# MK21F12 register map
Vendor: Freescale Semiconductor, Inc.; Series: Kinetis_K; File version: 1.6
CPU: CM4 r0p1, little endian, no MPU, FPU, VTOR, 4 interrupt priority bits
Registers are 32-bit, read-write, reset 0x0 unless marked. A register's access mark holds for its fields unless they carry their own. Offsets are from the block's base; [hi:lo] are bit positions; {n}, {i} and the like mark numbered series; 'fields as' and 'values as' point back to an identical list.

## FTFE_FlashConfig — Flash configuration field
Base 0x00000400; register names take the prefix NV_
0x00 BACKKEY3 8-bit ro reset 0xFF — Backdoor Comparison Key 3.
  [7:0] KEY — Backdoor Comparison Key.
0x01 BACKKEY2 8-bit ro reset 0xFF — Backdoor Comparison Key 2.
  [7:0] KEY — Backdoor Comparison Key.
0x02 BACKKEY1 8-bit ro reset 0xFF — Backdoor Comparison Key 1.
  [7:0] KEY — Backdoor Comparison Key.
0x03 BACKKEY0 8-bit ro reset 0xFF — Backdoor Comparison Key 0.
  [7:0] KEY — Backdoor Comparison Key.
0x04 BACKKEY7 8-bit ro reset 0xFF — Backdoor Comparison Key 7.
  [7:0] KEY — Backdoor Comparison Key.
0x05 BACKKEY6 8-bit ro reset 0xFF — Backdoor Comparison Key 6.
  [7:0] KEY — Backdoor Comparison Key.
0x06 BACKKEY5 8-bit ro reset 0xFF — Backdoor Comparison Key 5.
  [7:0] KEY — Backdoor Comparison Key.
0x07 BACKKEY4 8-bit ro reset 0xFF — Backdoor Comparison Key 4.
  [7:0] KEY — Backdoor Comparison Key.
0x08 FPROT3 8-bit ro reset 0xFF — Non-volatile P-Flash Protection 1 - Low Register
  [7:0] PROT — P-Flash Region Protect
0x09 FPROT2 8-bit ro reset 0xFF — Non-volatile P-Flash Protection 1 - High Register
  [7:0] PROT — P-Flash Region Protect
0x0A FPROT1 8-bit ro reset 0xFF — Non-volatile P-Flash Protection 0 - Low Register
  [7:0] PROT — P-Flash Region Protect
0x0B FPROT0 8-bit ro reset 0xFF — Non-volatile P-Flash Protection 0 - High Register
  [7:0] PROT — P-Flash Region Protect
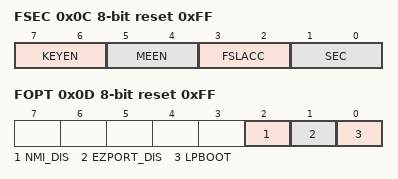
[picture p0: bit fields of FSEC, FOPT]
0x0C FSEC 8-bit ro reset 0xFF — Non-volatile Flash Security Register
  [7:6] KEYEN — Backdoor Key Security Enable
    2=Backdoor key access enabled; 3=Backdoor key access disabled
  [5:4] MEEN
    2=Mass erase is disabled; 3=Mass erase is enabled
  [3:2] FSLACC — Freescale Failure Analysis Access Code
    2=Freescale factory access denied; 3=Freescale factory access granted
  [1:0] SEC — Flash Security
    2=MCU security status is unsecure; 3=MCU security status is secure
0x0D FOPT 8-bit ro reset 0xFF — Non-volatile Flash Option Register
  [2] NMI_DIS
    0=NMI interrupts are always blocked; 1=NMI_b pin/interrupts reset default to enabled
  [1] EZPORT_DIS
    0=EzPort operation is disabled; 1=EzPort operation is enabled
  [0] LPBOOT
    0=Low-power boot; 1=Normal boot
0x0E FEPROT 8-bit ro reset 0xFF — Non-volatile EERAM Protection Register
  [7:0] EPROT
0x0F FDPROT 8-bit ro reset 0xFF — Non-volatile D-Flash Protection Register
  [7:0] DPROT — D-Flash Region Protect

## AXBS — Crossbar switch
Base 0x40004000; register names take the prefix AXBS_
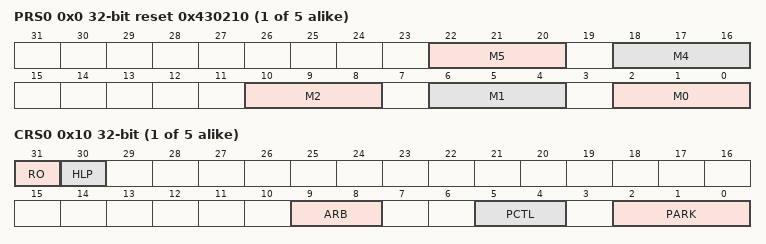
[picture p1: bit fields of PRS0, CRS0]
{0x0+0x100*i} PRS{i} (i=0..4) reset 0x430210 — Priority Registers Slave
  [all] fields
    0=This master has level 1, or highest, priority when accessing the slave port; {v}=This master has level {v+1} priority when accessing the slave port (v=1..6); 7=This master has level 8, or lowest, priority when accessing the slave port
  [22:20] M5 — Master 5 Priority. Sets the arbitration priority for this port on the associated slave port.
  [18:16] M4 — Master 4 Priority. Sets the arbitration priority for this port on the associated slave port.
  [10:8] M2 — Master 2 Priority. Sets the arbitration priority for this port on the associated slave port.
  [6:4] M1 — Master 1 Priority. Sets the arbitration priority for this port on the associated slave port.
  [2:0] M0 — Master 0 Priority. Sets the arbitration priority for this port on the associated slave port.
{0x10+0x100*i} CRS{i} (i=0..4) — Control Register
  [31] RO — Read Only
    0=The slave port's registers are writeable; 1=The slave port's registers are read-only and cannot be written. Attempted writes have no effect on the registers and result in a bus error response.
  [30] HLP — Halt Low Priority
    0=The low power mode request has the highest priority for arbitration on this slave port; 1=The low power mode request has the lowest initial priority for arbitration on this slave port
  [9:8] ARB — Arbitration Mode
    0=Fixed priority; 1=Round-robin, or rotating, priority
  [5:4] PCTL — Parking Control
    0=When no master makes a request, the arbiter parks the slave port on the master port defined by the PARK field; 1=When no master makes a request, the arbiter parks the slave port on the last master to be in control of the slave port; 2=When no master makes a request, the slave port is not parked on a master and the arbiter drives all outputs to a constant safe state
  [2:0] PARK
    {v}=Park on master port M{v} (v=0..7)
{0x800+0x100*i} MGPCR{i} (i=0..2) — Master General Purpose Control Register
  [2:0] AULB — Arbitrates On Undefined Length Bursts
    0=No arbitration is allowed during an undefined length burst; 1=Arbitration is allowed at any time during an undefined length burst; 2=Arbitration is allowed after four beats of an undefined length burst; 3=Arbitration is allowed after eight beats of an undefined length burst; 4=Arbitration is allowed after 16 beats of an undefined length burst
0xC00 MGPCR4 — Master General Purpose Control Register
  fields as MGPCR0
0xD00 MGPCR5 — Master General Purpose Control Register
  fields as MGPCR0

## Notices in the file
Redistribution and use in source and binary forms, with or without modification,
are permitted provided that the following conditions are met:
o Redistributions of source code must retain the above copyright notice, this list
of conditions and the following disclaimer.
o Redistributions in binary form must reproduce the above copyright notice, this
list of conditions and the following disclaimer in the documentation and/or
other materials provided with the distribution.
o Neither the name of Freescale Semiconductor, Inc. nor the names of its
contributors may be used to endorse or promote products derived from this
software without specific prior written permission.
THIS SOFTWARE IS PROVIDED BY THE COPYRIGHT HOLDERS AND CONTRIBUTORS "AS IS" AND
ANY EXPRESS OR IMPLIED WARRANTIES, INCLUDING, BUT NOT LIMITED TO, THE IMPLIED
WARRANTIES OF MERCHANTABILITY AND FITNESS FOR A PARTICULAR PURPOSE ARE
DISCLAIMED. IN NO EVENT SHALL THE COPYRIGHT HOLDER OR CONTRIBUTORS BE LIABLE FOR
ANY DIRECT, INDIRECT, INCIDENTAL, SPECIAL, EXEMPLARY, OR CONSEQUENTIAL DAMAGES
(INCLUDING, BUT NOT LIMITED TO, PROCUREMENT OF SUBSTITUTE GOODS OR SERVICES;
LOSS OF USE, DATA, OR PROFITS; OR BUSINESS INTERRUPTION) HOWEVER CAUSED AND ON
ANY THEORY OF LIABILITY, WHETHER IN CONTRACT, STRICT LIABILITY, OR TORT
(INCLUDING NEGLIGENCE OR OTHERWISE) ARISING IN ANY WAY OUT OF THE USE OF THIS
SOFTWARE, EVEN IF ADVISED OF THE POSSIBILITY OF SUCH DAMAGE.
